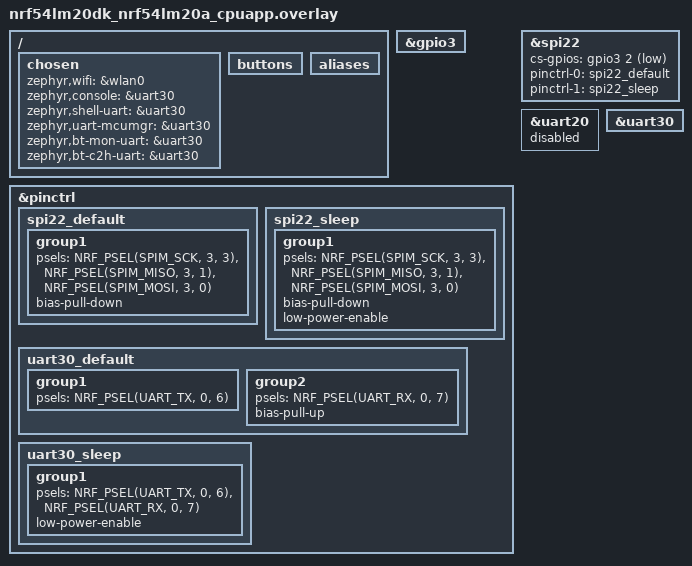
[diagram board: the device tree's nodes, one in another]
/*
 * Copyright (c) 2025 Nordic Semiconductor
 *
 * SPDX-License-Identifier: Apache-2.0
 */

#include "../nrf7002eb2_gpio_pins_2.dtsi"

/ {
	chosen {
		zephyr,wifi = &wlan0;
		zephyr,console = &uart30;
		zephyr,shell-uart = &uart30;
		zephyr,uart-mcumgr = &uart30;
		zephyr,bt-mon-uart = &uart30;
		zephyr,bt-c2h-uart = &uart30;
	};

	buttons {
		/delete-node/ button_3;
	};

	aliases {
		/delete-property/ sw3;
	};
};

&gpio3 {
	status = "okay";
};

&pinctrl {
	spi22_default: spi22_default {
		group1 {
			psels = <NRF_PSEL(SPIM_SCK, 3, 3)>,
				<NRF_PSEL(SPIM_MISO, 3, 1)>,
				<NRF_PSEL(SPIM_MOSI, 3, 0)>;
			bias-pull-down;
		};
	};

	spi22_sleep: spi22_sleep {
		group1 {
			psels = <NRF_PSEL(SPIM_SCK, 3, 3)>,
				<NRF_PSEL(SPIM_MISO, 3, 1)>,
				<NRF_PSEL(SPIM_MOSI, 3, 0)>;
			bias-pull-down;
			low-power-enable;
		};
	};

	uart30_default: uart30_default {
		group1 {
			psels = <NRF_PSEL(UART_TX, 0, 6)>;
		};

		group2 {
			psels = <NRF_PSEL(UART_RX, 0, 7)>;
			bias-pull-up;
		};
	};

	uart30_sleep: uart30_sleep {
		group1 {
			psels = <NRF_PSEL(UART_TX, 0, 6)>,
				<NRF_PSEL(UART_RX, 0, 7)>;
			low-power-enable;
		};
	};
};

&spi22 {
	status = "okay";
	cs-gpios = <&gpio3 2 GPIO_ACTIVE_LOW>;
	pinctrl-0 = <&spi22_default>;
	pinctrl-1 = <&spi22_sleep>;
	pinctrl-names = "default", "sleep";
};

/* uart20 has pin conflicts with EB-II shield hence disabling that
 * and enabling uart30 as console port.
 */
&uart20 {
	status = "disabled";
};

&uart30 {
	status = "okay";
};
